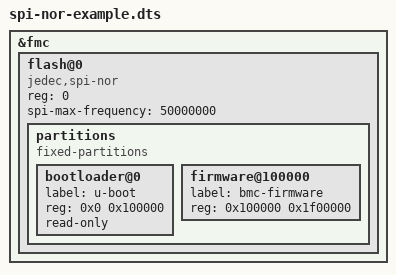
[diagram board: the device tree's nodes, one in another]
/dts-v1/;
/plugin/;

&fmc {
	status = "okay";
	#address-cells = <1>;
	#size-cells = <0>;

	flash@0 {
		compatible = "jedec,spi-nor";
		reg = <0>;
		spi-max-frequency = <50000000>;
		#address-cells = <1>;
		#size-cells = <1>;

		partitions {
			compatible = "fixed-partitions";
			#address-cells = <1>;
			#size-cells = <1>;
			bootloader@0 { label = "u-boot"; reg = <0x0 0x100000>; read-only; };
			firmware@100000 { label = "bmc-firmware"; reg = <0x100000 0x1f00000>; };
		};
	};
};

